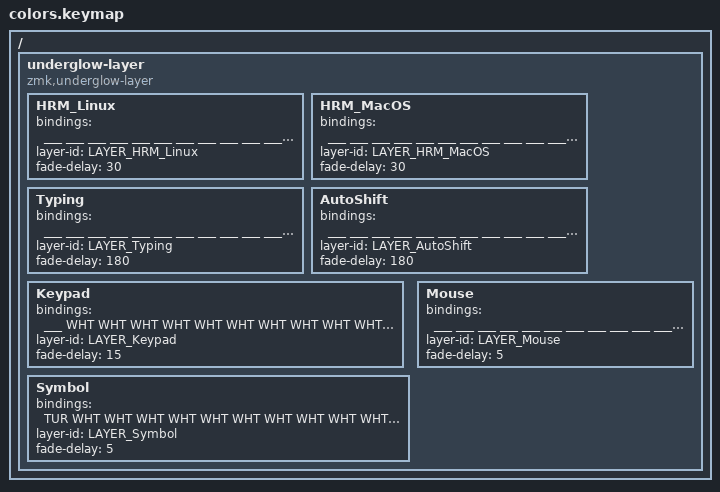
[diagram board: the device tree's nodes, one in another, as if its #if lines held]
///////////////////////////////////////////////////////////////
// TailorKey 4.2j Go60 - RGB Lighting 
// Paste this configuration into the Custom Device-tree section
// For more into, see https://sites.google.com/view/tailorkey
////////////////////////////////////////////////////////////////

#if __has_include(<dt-bindings/zmk/rgb_colors.h>)
  //
  // Color definitions with conflict guard to prevent
  // accidental redefinition of common abbreviations.
  //
  #if defined(RED) || defined(RED_RGB) || \
      defined(COR) || defined(COR_RGB) || \
      defined(ORN) || defined(ORN_RGB) || \
      defined(GDN) || defined(GDN_RGB) || \
      defined(GOL) || defined(GOL_RGB) || \
      defined(YLW) || defined(YLW_RGB) || \
      defined(CHU) || defined(CHU_RGB) || \
      defined(GRN) || defined(GRN_RGB) || \
      defined(SPG) || defined(SPG_RGB) || \
      defined(CYN) || defined(CYN_RGB) || \
      defined(AZU) || defined(AZU_RGB) || \
      defined(TEA) || defined(TEA_RGB) || \
      defined(TUR) || defined(TUR_RGB) || \
      defined(BLU) || defined(BLU_RGB) || \
      defined(PUR) || defined(PUR_RGB) || \
      defined(MAJ) || defined(MAJ_RGB) || \
      defined(PNK) || defined(PNK_RGB) || \
      defined(WHT) || defined(WHT_RGB) || \
      defined(BLK) || defined(BLK_RGB) || \
      defined(___) || \
      defined(DUG) || defined(DUG_RGB) || \
      defined(LAC) || defined(LAC_RGB) || \
      defined(BSL) || defined(BNL) || defined(BCL) || \
      defined(SSL) || defined(SNL) || defined(SCL) || \
      defined(FST) || defined(WRP) || defined(SLO)
  #error "Naming conflict: 3-letter color abbreviation already defined!"
  #endif

  //
  // Color definitions from QMK
  // https://github.com/qmk/qmk_firmware/blob/master/quantum/color.h
  //
  #define RED_RGB 0xFF0000 // #FF0000 RED      => RED (red)
  #define COR_RGB 0xFF7C4D // #FF7C4D CORAL    => COR (coral)
  #define ORN_RGB 0xFF8000 // #FF8000 ORANGE   => ORN (ornj)
  #define GDN_RGB 0xD9A521 // #D9A521 GOLDNROD => GDN (gold'nrod)
  #define GOL_RGB 0xFFD900 // #FFD900 GOLD     => GOL (gold)
  #define YLW_RGB 0xFFFF00 // #FFFF00 YELLOW   => YLW (yellow)
  #define CHU_RGB 0x80FF00 // #80FF00 CHARTRSE => CHU (chartreuse)
  #define GRN_RGB 0x00FF00 // #00FF00 GREEN    => GRN (green)
  #define SPG_RGB 0x00FF80 // #00FF80 SPRINGRN => SPG (spring green)
  #define CYN_RGB 0x00FFFF // #00FFFF CYAN     => CYN (sigh-an)
  #define AZU_RGB 0x99F5FF // #99F5FF AZURE    => AZU (a-zur)
  #define TEA_RGB 0x008080 // #008080 TEAL     => TEA (teel)
  #define TUR_RGB 0x476E6A // #476E6A TURQUOIS => TUR (turquoise)
  #define BLU_RGB 0x0000FF // #0000FF BLUE     => BLU (bloo)
  #define PUR_RGB 0x7A00FF // #7A00FF PURPLE   => PUR (purp)
  #define MAJ_RGB 0xFF00FF // #FF00FF MAGENTA  => MAJ (mah-jenta)
  #define PNK_RGB 0xFF80BF // #FF80BF PINK     => PNK (pink)
  #define WHT_RGB 0xFFFFFF // #FFFFFF WHITE    => WHT (white)
  #define BLK_RGB 0x000000 // #000000 BLACK    => BLK (blak)

  //
  // Color definitions from MoErgo
  // https://github.com/moergo-sc/zmk/blob/aca523dfce9b6447ffd19d833b791d44f1f286de/app/src/rgb_underglow.c#L259-L265
  //
  #define DUG_RGB 0x00ff68 // #00ff68 DULL_GRN => DUG (dull green)
  #define LAC_RGB 0x6b1fce // #6b1fce LILAC    => LAC (lilac)

  //
  // Underglow for the colors above
  //
  #define RED &ug RED_RGB
  #define COR &ug COR_RGB
  #define ORN &ug ORN_RGB
  #define GDN &ug GDN_RGB
  #define GOL &ug GOL_RGB
  #define YLW &ug YLW_RGB
  #define CHU &ug CHU_RGB
  #define GRN &ug GRN_RGB
  #define SPG &ug SPG_RGB
  #define CYN &ug CYN_RGB
  #define AZU &ug AZU_RGB
  #define TEA &ug TEA_RGB
  #define TUR &ug TUR_RGB
  #define BLU &ug BLU_RGB
  #define PUR &ug PUR_RGB
  #define MAJ &ug MAJ_RGB
  #define PNK &ug PNK_RGB
  #define WHT &ug WHT_RGB
  #define ___ &ug BLK_RGB
  #define DUG &ug DUG_RGB
  #define LAC &ug LAC_RGB

  //
  // Underglow for keyboard locks on the Base layer
  //
  #define BSL &ug_sl BLK_RGB RED_RGB // ScrollLock COLOR_OFF COLOR_ON
  #define BNL &ug_nl BLK_RGB RED_RGB // NumLock    COLOR_OFF COLOR_ON
  #define BCL &ug_cl BLK_RGB RED_RGB // CapsLock   COLOR_OFF COLOR_ON

  // ==== PER-KEY-RGB PER-LAYER-RGB ====
  / {
    underglow-layer {
      compatible = "zmk,underglow-layer";
   
      #ifdef LAYER_HRM_Linux
      HRM_Linux {
        bindings = <
          ___ ___ ___ ___ ___ ___                                     ___ ___ ___ ___ ___ ___
          ___ ___ ___ ___ ___ ___                                     ___ ___ ___ ___ ___ ___
          ___ MAJ CYN CHU RED ___                                     ___ RED CHU CYN MAJ ___
          WHT ___ ___ ___ ___ ___                                     ___ ___ ___ ___ ___ WHT
                  ___ WHT WHT                                             WHT ___ ___
                                      WHT ___ ___     WHT ___ ___
        >;
        layer-id = <LAYER_HRM_Linux>;
        fade-delay = <30>;
      };
      #endif

      #ifdef LAYER_HRM_MacOS
      HRM_MacOS {
        bindings = <
          ___ ___ ___ ___ ___ ___                                     ___ ___ ___ ___ ___ ___
          ___ ___ ___ ___ ___ ___                                     ___ ___ ___ ___ ___ ___
          ___ CHU CYN MAJ RED ___                                     ___ RED MAJ CYN CHU ___
          WHT ___ ___ ___ ___ ___                                     ___ ___ ___ ___ ___ WHT
                  ___ WHT WHT                                             WHT ___ ___
                                      WHT ___ ___     WHT ___ ___
        >;
        layer-id = <LAYER_HRM_MacOS>;
        fade-delay = <30>;
      };
      #endif

      #ifdef LAYER_Typing
      Typing {
        bindings = <
          ___ ___ ___ ___ ___ ___                                     ___ ___ ___ ___ ___ ___
          ___ ___ ___ ___ ___ ___                                     ___ ___ ___ ___ ___ ___
          ___ ___ ___ ___ ___ ___                                     ___ ___ ___ ___ ___ ___
          COR ___ ___ ___ ___ ___                                     ___ ___ ___ ___ ___ COR
                  ___ COR COR                                             COR ___ ___
                                      COR ___ ___     COR ___ ___
        >;
        layer-id = <LAYER_Typing>;
        fade-delay = <180>;
      };
      #endif

      #ifdef LAYER_AutoShift
      AutoShift {
        bindings = <
          ___ ___ ___ ___ ___ ___                                     ___ ___ ___ ___ ___ ___
          ___ ___ ___ ___ ___ ___                                     ___ ___ ___ ___ ___ ___
          ___ ___ ___ ___ ___ ___                                     ___ ___ ___ ___ ___ ___
          SPG ___ ___ ___ ___ ___                                     ___ ___ ___ ___ ___ SPG
                  ___ SPG SPG                                             SPG ___ ___
                                      SPG ___ ___     SPG ___ ___
        >;
        layer-id = <LAYER_AutoShift>;
        fade-delay = <180>;
      };
      #endif

      #ifdef LAYER_Keypad
      Keypad {
        bindings = <
          ___ WHT WHT WHT WHT WHT                                     WHT WHT WHT WHT WHT WHT
          ___ PNK GRN GRN GRN GRN                                     YLW YLW YLW YLW YLW WHT
          ___ MAJ GRN GRN GRN GRN                                     YLW YLW YLW YLW YLW ORN
          ___ ___ ___ ___ ___ ___                                     YLW YLW YLW YLW YLW ___
                  ___ ___ ___                                             ___ YLW YLW
                                      ___ ___ ___     ___ ___ ___
        >;
        layer-id = <LAYER_Keypad>;
        fade-delay = <15>;
      };
      #endif

      #ifdef LAYER_Symbol
      Symbol {
        bindings = <
          TUR WHT WHT WHT WHT WHT                                     WHT WHT WHT WHT WHT WHT
          ___ GDN BLU BLU BLU BLU                                     GRN GRN GRN GRN PNK WHT
          ___ COR BLU BLU BLU BLU                                     GRN GRN GRN GRN MAJ PUR
          ___ BLU BLU BLU BLU BLU                                     BLU BLU BLU BLU BLU ___
                  BLU ___ ___                                             ___ ___ BLU
                                      ___ ___ ___     ___ ___ ___
        >;
        layer-id = <LAYER_Symbol>;
        fade-delay = <5>;
      };
      #endif

      #ifdef LAYER_Mouse
      Mouse {
        bindings = <
          ___ ___ ___ ___ ___ ___                                     ___ ___ ___ ___ ___ ___
          ___ ___ ___ TEA ___ ___                                     ___ ___ TEA ___ ___ ___
          ___ ___ TEA TEA TEA ___                                     ___ TEA TEA TEA ___ ___
          ___ ___ ___ ___ ___ ___                                     ___ ___ ___ ___ ___ ___
                  ___ ___ ___                                             ___ ___ ___
                                      TEA TEA TEA     TEA TEA TEA
        >;
        layer-id = <LAYER_Mouse>;
        fade-delay = <5>;
      };
      #endif

    };
  };
  // ==== PER-KEY-RGB PER-LAYER-RGB =====

  #undef RED
  #undef RED_RGB
  #undef COR
  #undef COR_RGB
  #undef ORN
  #undef ORN_RGB
  #undef GDN
  #undef GDN_RGB
  #undef GOL
  #undef GOL_RGB
  #undef YLW
  #undef YLW_RGB
  #undef CHU
  #undef CHU_RGB
  #undef GRN
  #undef GRN_RGB
  #undef SPG
  #undef SPG_RGB
  #undef CYN
  #undef CYN_RGB
  #undef AZU
  #undef AZU_RGB
  #undef TEA
  #undef TEA_RGB
  #undef TUR
  #undef TUR_RGB
  #undef BLU
  #undef BLU_RGB
  #undef PUR
  #undef PUR_RGB
  #undef MAJ
  #undef MAJ_RGB
  #undef PNK
  #undef PNK_RGB
  #undef WHT
  #undef WHT_RGB
  #undef BLK
  #undef BLK_RGB
  #undef ___
  #undef DUG
  #undef DUG_RGB
  #undef LAC
  #undef LAC_RGB

  #undef BSL
  #undef BNL
  #undef BCL

  #undef SSL
  #undef SNL
  #undef SCL
#endif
